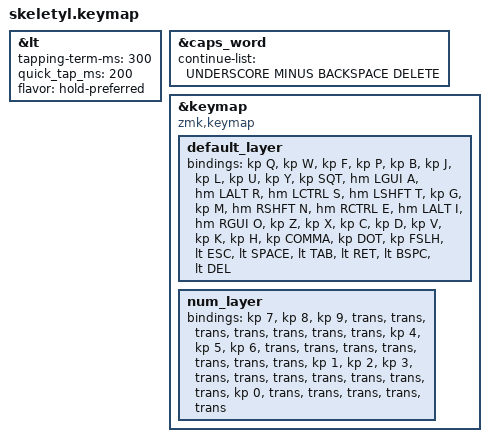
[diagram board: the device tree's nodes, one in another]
#include <behaviors.dtsi>
#include <dt-bindings/zmk/keys.h>
#include <dt-bindings/zmk/bt.h>

#define DEFAULT 0
#define NUM 1

&lt {
  tapping-term-ms = <300>;
  quick_tap_ms = <200>;
  flavor = "hold-preferred";
};

&caps_word {
  continue-list = <UNDERSCORE MINUS BACKSPACE DELETE>;
};

&keymap {
    compatible = "zmk,keymap";

    // Default Layer
    default_layer {
        bindings = <
            &kp Q      &kp W        &kp F          &kp P          &kp B            &kp J        &kp L        &kp U        &kp Y       &kp SQT
            &hm LGUI A &hm LALT R   &hm LCTRL S    &hm LSHFT T    &kp G            &kp M        &hm RSHFT N  &hm RCTRL E  &hm LALT I  &hm RGUI O
            &kp Z      &kp X        &kp C          &kp D          &kp V            &kp K        &kp H        &kp COMMA    &kp DOT     &kp FSLH
                                    &lt ESC        &lt SPACE      &lt TAB          &lt RET      &lt BSPC     &lt DEL
        >;
    };

    // NUM Layer (example for numeric layer)
    num_layer {
        bindings = <
            &kp 7   &kp 8   &kp 9   &trans  &trans      &trans  &trans  &trans  &trans  &trans
            &kp 4   &kp 5   &kp 6   &trans  &trans      &trans  &trans  &trans  &trans  &trans
            &kp 1   &kp 2   &kp 3   &trans  &trans      &trans  &trans  &trans  &trans  &trans
                            &kp 0   &trans  &trans      &trans  &trans  &trans

        >;
    };
};
